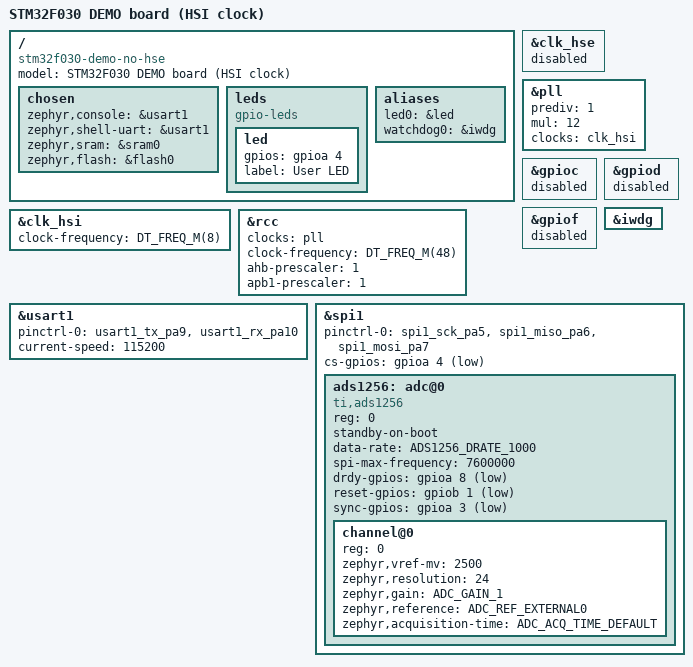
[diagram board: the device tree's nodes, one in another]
/*
 * Copyright (c) 2019 Antony Pavlov <antonynpavlov@gmail.com>
 *
 * SPDX-License-Identifier: Apache-2.0
 */

/dts-v1/;
#include <st/f0/stm32f030X4.dtsi>
#include <st/f0/stm32f030f4px-pinctrl.dtsi>
#include <zephyr/dt-bindings/gpio/gpio.h>

/*
 * Variant of stm32f030_demo for boards that are populated without the 8 MHz HSE
 * crystal.  The stock devicetree enables clk_hse, and the clock driver then
 * spins in `while (LL_RCC_HSE_IsReady() != 1) {}` in
 * set_up_fixed_clock_sources(), which looks like dead silicon: the image never
 * reaches the console.  Run the PLL from HSI instead.
 *
 * With HSI at 8 MHz the F0 PLL input is HSI/2 = 4 MHz, so mul = 12 gives the
 * same 48 MHz SYSCLK as the crystal build.
 */

/ {
	compatible = "stm32f030-demo-no-hse";
	model = "STM32F030 DEMO board (HSI clock)";

	chosen {
		zephyr,console = &usart1;
		zephyr,shell-uart = &usart1;
		zephyr,sram = &sram0;
		zephyr,flash = &flash0;
	};

	leds {
		compatible = "gpio-leds";

		led: led {
			gpios = <&gpioa 4 GPIO_ACTIVE_HIGH>;
			label = "User LED";
		};
	};

	aliases {
		led0 = &led;
		watchdog0 = &iwdg;
	};
};

/* No crystal on this variant: keep HSE off so the driver does not wait for it. */
&clk_hse {
	status = "disabled";
};

&clk_hsi {
	clock-frequency = <DT_FREQ_M(8)>;
	status = "okay";
};

&pll {
	prediv = <1>;
	mul = <12>;
	clocks = <&clk_hsi>;
	status = "okay";
};

&rcc {
	clocks = <&pll>;
	clock-frequency = <DT_FREQ_M(48)>;
	ahb-prescaler = <1>;
	apb1-prescaler = <1>;
};

/* Due to limited available memory, don't enable gpioc,d,e,f */
&gpioc {
	status = "disabled";
};

&gpiod {
	status = "disabled";
};

&gpiof {
	status = "disabled";
};

&usart1 {
	pinctrl-0 = <&usart1_tx_pa9 &usart1_rx_pa10>;
	pinctrl-names = "default";
	current-speed = <115200>;
	status = "okay";
};

&iwdg {
	status = "okay";
};

/*
 * External TI ADS1256 (8 channel, 24 bit) wired on SPI1:
 *   SCK PA5, MISO PA6, MOSI PA7, CS PA4, DRDY PA8, RESET PB1, SYNC PA3.
 * The chip is part of this board variant, so its wiring lives here; samples
 * only need to alias it (adc0 = &ads1256).
 */
&spi1 {
	pinctrl-0 = <&spi1_sck_pa5 &spi1_miso_pa6 &spi1_mosi_pa7>;
	pinctrl-names = "default";
	cs-gpios = <&gpioa 4 (GPIO_ACTIVE_LOW | GPIO_PULL_UP)>;
	status = "okay";

	ads1256: adc@0 {
		compatible = "ti,ads1256";
		reg = <0>;
		#io-channel-cells = <1>;
		#address-cells = <1>;
		#size-cells = <0>;
		status = "okay";
		standby-on-boot;
		data-rate = "ADS1256_DRATE_1000";
		spi-max-frequency = <7600000>;
		drdy-gpios = <&gpioa 8 GPIO_ACTIVE_LOW>;
		reset-gpios = <&gpiob 1 GPIO_ACTIVE_LOW>;
		sync-gpios = <&gpioa 3 GPIO_ACTIVE_LOW>;

		channel@0 {
			reg = <0>;
			zephyr,vref-mv = <2500>;
			zephyr,resolution = <24>;
			zephyr,gain = "ADC_GAIN_1";
			zephyr,reference = "ADC_REF_EXTERNAL0";
			zephyr,acquisition-time = <ADC_ACQ_TIME_DEFAULT>;
		};
	};
};
